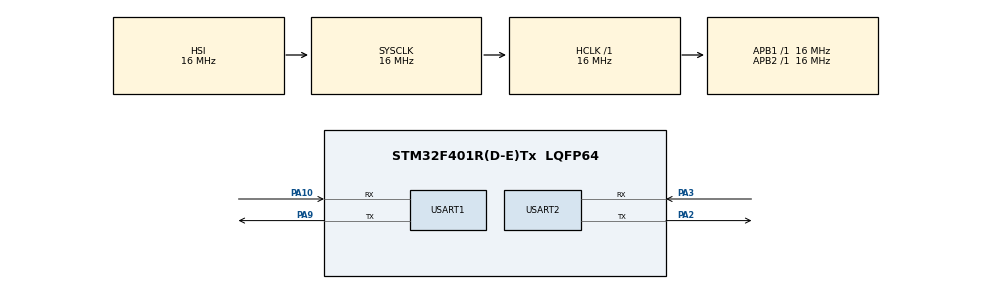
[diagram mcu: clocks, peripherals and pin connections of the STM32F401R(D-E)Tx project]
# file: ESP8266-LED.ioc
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Mcu.Family=STM32F4
Mcu.Name=STM32F401R(D-E)Tx
Mcu.Package=LQFP64
NVIC.PriorityGroup=NVIC_PRIORITYGROUP_4
PA10.Mode=Asynchronous
PA10.Signal=USART1_RX
PA13.Mode=Serial_Wire
PA13.Signal=SYS_JTMS-SWDIO
PA14.Mode=Serial_Wire
PA14.Signal=SYS_JTCK-SWCLK
PA2.Mode=Asynchronous
PA2.Signal=USART2_TX
PA3.Mode=Asynchronous
PA3.Signal=USART2_RX
PA9.Mode=Asynchronous
PA9.Signal=USART1_TX
ProjectManager.HeapSize=0x200
ProjectManager.StackSize=0x400
ProjectManager.TargetToolchain=STM32CubeIDE
RCC.AHBFreq_Value=16000000
RCC.APB1Freq_Value=16000000
RCC.APB2Freq_Value=16000000
RCC.CortexFreq_Value=16000000
RCC.HSE_VALUE=25000000
RCC.HSI_VALUE=16000000
RCC.LSE_VALUE=32768
RCC.SYSCLKFreq_VALUE=16000000
RCC.VCOOutputFreq_Value=192000000
USART1.VirtualMode=VM_ASYNC
USART2.VirtualMode=VM_ASYNC
board=custom

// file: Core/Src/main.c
/* USER CODE BEGIN Header */
/**
  ******************************************************************************
  * @file           : main.c
  * @brief          : Main program body
  ******************************************************************************
  * @attention
  *
  * Copyright (c) 2023 STMicroelectronics.
  * All rights reserved.
  *
  * This software is licensed under terms that can be found in the LICENSE file
  * in the root directory of this software component.
  * If no LICENSE file comes with this software, it is provided AS-IS.
  *
  ******************************************************************************
  */
/* USER CODE END Header */
#include "main.h"

/* USER CODE BEGIN Includes */
#include "string.h"
#include "stdio.h"
#include "stdbool.h"
#include "UartRingbuffer.h"
/* USER CODE END Includes */

UART_HandleTypeDef huart1;
UART_HandleTypeDef huart2;

void SystemClock_Config(void);
static void MX_GPIO_Init(void);
static void MX_USART1_UART_Init(void);
static void MX_USART2_UART_Init(void);

/* USER CODE BEGIN 0 */
#define device_uart &huart1
#define pc_uart &huart2
/* USER CODE END 0 */

int main(void)
{

  /* MCU Configuration--------------------------------------------------------*/

  /* Reset of all peripherals, Initializes the Flash interface and the Systick. */
  HAL_Init();

  /* Configure the system clock */
  SystemClock_Config();

  /* Initialize all configured peripherals */
  MX_GPIO_Init();
  MX_USART1_UART_Init();
  MX_USART2_UART_Init();
  /* USER CODE BEGIN 2 */
  Ringbuf_init();
  /* USER CODE END 2 */

  /* Infinite loop */
  /* USER CODE BEGIN WHILE */
  while (1)
  {    if (IsDataAvailable(pc_uart))
  {
   int data = Uart_read(pc_uart);
   Uart_write(data, wifi_uart);
  }

  if (IsDataAvailable(wifi_uart))
  {
   int data = Uart_read(wifi_uart);
   Uart_write(data, pc_uart);
  }
    /* USER CODE END WHILE */

  }
}

void SystemClock_Config(void)
{
  RCC_OscInitTypeDef RCC_OscInitStruct = {0};
  RCC_ClkInitTypeDef RCC_ClkInitStruct = {0};

  /** Configure the main internal regulator output voltage
  */
  __HAL_RCC_PWR_CLK_ENABLE();
  __HAL_PWR_VOLTAGESCALING_CONFIG(PWR_REGULATOR_VOLTAGE_SCALE2);
  /** Initializes the RCC Oscillators according to the specified parameters
  * in the RCC_OscInitTypeDef structure.
  */
  RCC_OscInitStruct.OscillatorType = RCC_OSCILLATORTYPE_HSI;
  RCC_OscInitStruct.HSIState = RCC_HSI_ON;
  RCC_OscInitStruct.HSICalibrationValue = RCC_HSICALIBRATION_DEFAULT;
  RCC_OscInitStruct.PLL.PLLState = RCC_PLL_NONE;
  if (HAL_RCC_OscConfig(&RCC_OscInitStruct) != HAL_OK)
  {
    Error_Handler();
  }
  /** Initializes the CPU, AHB and APB buses clocks
  */
  RCC_ClkInitStruct.ClockType = RCC_CLOCKTYPE_HCLK|RCC_CLOCKTYPE_SYSCLK
                              |RCC_CLOCKTYPE_PCLK1|RCC_CLOCKTYPE_PCLK2;
  RCC_ClkInitStruct.SYSCLKSource = RCC_SYSCLKSOURCE_HSI;
  RCC_ClkInitStruct.AHBCLKDivider = RCC_SYSCLK_DIV1;
  RCC_ClkInitStruct.APB1CLKDivider = RCC_HCLK_DIV1;
  RCC_ClkInitStruct.APB2CLKDivider = RCC_HCLK_DIV1;

  if (HAL_RCC_ClockConfig(&RCC_ClkInitStruct, FLASH_LATENCY_0) != HAL_OK)
  {
    Error_Handler();
  }
}

static void MX_USART1_UART_Init(void)
{

  huart1.Instance = USART1;
  huart1.Init.BaudRate = 115200;
  huart1.Init.WordLength = UART_WORDLENGTH_8B;
  huart1.Init.StopBits = UART_STOPBITS_1;
  huart1.Init.Parity = UART_PARITY_NONE;
  huart1.Init.Mode = UART_MODE_TX_RX;
  huart1.Init.HwFlowCtl = UART_HWCONTROL_NONE;
  huart1.Init.OverSampling = UART_OVERSAMPLING_16;
  if (HAL_UART_Init(&huart1) != HAL_OK)
  {
    Error_Handler();
  }

}

static void MX_USART2_UART_Init(void)
{

  huart2.Instance = USART2;
  huart2.Init.BaudRate = 115200;
  huart2.Init.WordLength = UART_WORDLENGTH_8B;
  huart2.Init.StopBits = UART_STOPBITS_1;
  huart2.Init.Parity = UART_PARITY_NONE;
  huart2.Init.Mode = UART_MODE_TX_RX;
  huart2.Init.HwFlowCtl = UART_HWCONTROL_NONE;
  huart2.Init.OverSampling = UART_OVERSAMPLING_16;
  if (HAL_UART_Init(&huart2) != HAL_OK)
  {
    Error_Handler();
  }

}

static void MX_GPIO_Init(void)
{

  /* GPIO Ports Clock Enable */
  __HAL_RCC_GPIOA_CLK_ENABLE();

}

void Error_Handler(void)
{
  __disable_irq();
  while (1)
  {
  }
}
